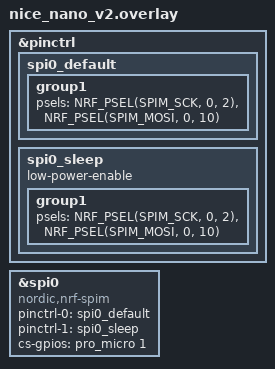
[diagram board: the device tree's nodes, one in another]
&pinctrl {
    spi0_default: spi0_default {
        group1 {
            psels = <NRF_PSEL(SPIM_SCK, 0, 2)>,
                    <NRF_PSEL(SPIM_MOSI, 0, 10)>;
        };
    };

    spi0_sleep: spi0_sleep {
        group1 {
            psels = <NRF_PSEL(SPIM_SCK, 0, 2)>,
                    <NRF_PSEL(SPIM_MOSI, 0, 10)>;
        };
        low-power-enable;
    };
};

&spi0 {
    compatible = "nordic,nrf-spim";
    status = "okay";
    pinctrl-0 = <&spi0_default>;
    pinctrl-1 = <&spi0_sleep>;
    pinctrl-names = "default", "sleep";
};

&spi0 {
    cs-gpios = <&pro_micro 1 GPIO_ACTIVE_HIGH>;
};

nice_view_spi: &spi0 {
    pinctrl-0 = <&spi0_default>;
    pinctrl-1 = <&spi0_sleep>;
    pinctrl-names = "default", "sleep";
};

